# pwrseq_me18 register map
Registers are access not given, no defined reset value unless marked. A register's access mark holds for its fields unless they carry their own. Offsets are from the block's base; lines under a group give offsets from that group; [hi:lo] are bit positions; {n}, {i} and the like mark numbered series; 'fields as' and 'values as' point back to an identical list; <NAME> marks a mode.

## Memory map
0x40006800 PWRSEQ size 0x400 — Power Sequencer / Low Power Control Register.

## PWRSEQ — Power Sequencer / Low Power Control Register.
Base 0x40006800
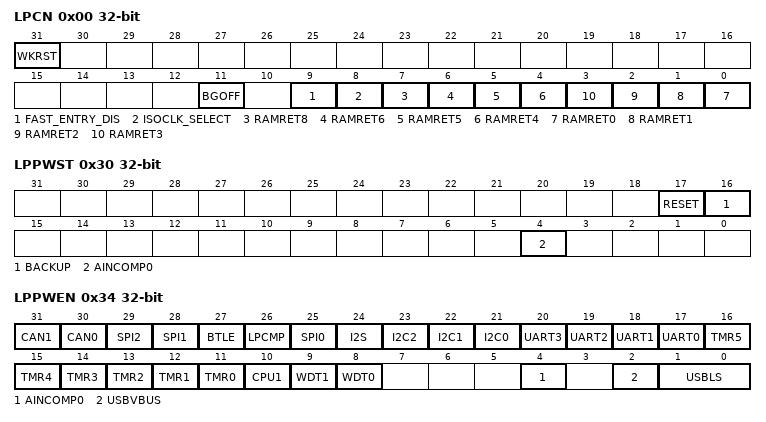
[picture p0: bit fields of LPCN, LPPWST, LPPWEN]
0x00 LPCN — Low Power Control Register.
  [31] WKRST — Reset wakeup status registers
  [11] BGOFF — Bandgap OFF. This controls the System Bandgap in DeepSleep mode.
    0=on (Bandgap is always ON.); 1=off (Bandgap is OFF in DeepSleep mode (default).)
  [9] FAST_ENTRY_DIS — Fast Low Power mode entry disable
  [8] ISOCLK_SELECT — 0 = PCLK 1= ISO CLK use for RISV in Low power mode
  [7] RAMRET8 — System RAM retention in BACKUP mode. RAM7 is retained if any of RAM0 to RAM6 is retained.
    0=dis (Disable Ram Retention.); 1=en (Enable System RAM 3 retention.)
  [6] RAMRET6 — System RAM retention in BACKUP mode. These two bits are used in conjuction with RREGEN bit.
    values as RAMRET8
  [5] RAMRET5 — System RAM retention in BACKUP mode. These two bits are used in conjuction with RREGEN bit.
    values as RAMRET8
  [4] RAMRET4 — System RAM retention in BACKUP mode. These two bits are used in conjuction with RREGEN bit.
    values as RAMRET8
  [n] RAMRET{n} (n=0..3) — System RAM retention in BACKUP mode. These two bits are used in conjuction with RREGEN bit.
    0=dis (Disable Ram Retention.); 1=en (Enable System RAM {n} retention.)
0x04 LPWKST0 — Low Power I/O Wakeup Status Register 0. This register indicates the low power wakeup status for GPIO0.
  [0] WAKEST — Wakeup IRQ flags (write ones to clear). One or more of these bits will be set when the corresponding dedicated GPIO pin (s) transition (s) from low to high or high to low. If GPIO wakeup source is selected, using PM.GPIOWKEN register, and the corresponding bit is also selected in LPWKEN register, an interrupt will be gnerated to wake up the CPU from a low power mode.
0x08 LPWKEN0 — Low Power I/O Wakeup Enable Register 0. This register enables low power wakeup functionality for GPIO0.
  [30:0] WAKEEN — Enable wakeup. These bits allow wakeup from the corresponding GPIO pin (s) on transition (s) from low to high or high to low when PM.GPIOWKEN is set. Wakeup status is indicated in PPWKST register.
0x0C LPWKST1 — Low Power I/O Wakeup Status Register 1. This register indicates the low power wakeup status for GPIO1.
  [9:0] WAKEST — Wakeup IRQ flags (write ones to clear). One or more of these bits will be set when the corresponding dedicated GPIO pin (s) transition (s) from low to high or high to low. If GPIO wakeup source is selected, using PM.GPIOWKEN register, and the corresponding bit is also selected in LPWKEN register, an interrupt will be gnerated to wake up the CPU from a low power mode.
0x10 LPWKEN1 — Low Power I/O Wakeup Enable Register 1. This register enables low power wakeup functionality for GPIO1.
  [9:0] WAKEEN — Enable wakeup. These bits allow wakeup from the corresponding GPIO pin (s) on transition (s) from low to high or high to low when PM.GPIOWKEN is set. Wakeup status is indicated in PPWKST register.
0x14 LPWKST2 — Low Power I/O Wakeup Status Register 2. This register indicates the low power wakeup status for GPIO2.
  [7:0] WAKEST — Wakeup IRQ flags (write ones to clear). One or more of these bits will be set when the corresponding dedicated GPIO pin (s) transition (s) from low to high or high to low. If GPIO wakeup source is selected, using PM.GPIOWKEN register, and the corresponding bit is also selected in LPWKEN register, an interrupt will be gnerated to wake up the CPU from a low power mode.
0x18 LPWKEN2 — Low Power I/O Wakeup Enable Register 2. This register enables low power wakeup functionality for GPIO2.
  [7:0] WAKEEN — Enable wakeup. These bits allow wakeup from the corresponding GPIO pin (s) on transition (s) from low to high or high to low when PM.GPIOWKEN is set. Wakeup status is indicated in PPWKST register.
0x1C LPWKST3 — Low Power I/O Wakeup Status Register 3. This register indicates the low power wakeup status for GPIO3.
  [1:0] WAKEST — Wakeup IRQ flags (write ones to clear). One or more of these bits will be set when the corresponding dedicated GPIO pin (s) transition (s) from low to high or high to low. If GPIO wakeup source is selected, using PM.GPIOWKEN register, and the corresponding bit is also selected in LPWKEN register, an interrupt will be gnerated to wake up the CPU from a low power mode.
0x20 LPWKEN3 — Low Power I/O Wakeup Enable Register 3. This register enables low power wakeup functionality for GPIO3.
  [1:0] WAKEEN — Enable wakeup. These bits allow wakeup from the corresponding GPIO pin (s) on transition (s) from low to high or high to low when PM.GPIOWKEN is set. Wakeup status is indicated in PPWKST register.
0x24 LPWKST4 — Low Power I/O Wakeup Status Register 4. This register indicates the low power wakeup status for GPIO4.
  fields as LPWKST3
0x28 LPWKEN4 — Low Power I/O Wakeup Enable Register 4. This register enables low power wakeup functionality for GPIO4.
  fields as LPWKEN3
0x30 LPPWST — Low Power Peripheral Wakeup Status Register.
  [17] RESET — Reset Detected Wakeup Flag.
  [16] BACKUP — Backup Mode Wakeup Flag.
  [4] AINCOMP0 — Analog Input Comparator Wakeup Flag.
0x34 LPPWEN — Low Power Peripheral Wakeup Enable Register.
  [31] CAN1 — CAN1 Wakeup Enable. This bit allows wakeup from the CAN1.
  [30] CAN0 — CAN0 Wakeup Enable. This bit allows wakeup from the CAN0.
  [29] SPI2 — SPI2 Wakeup Enable. This bit allows wakeup from the SPI2.
  [28] SPI1 — SPI1 Wakeup Enable. This bit allows wakeup from the SPI1.
  [27] BTLE — BTLE Wakeup Enable. This bit allows wakeup from the BTLE.
  [26] LPCMP — LPCMP Wakeup Enable. This bit allows wakeup from the LPCMP.
  [25] SPI0 — SPI0 Wakeup Enable. This bit allows wakeup from the SPI0.
  [24] I2S — I2S Wakeup Enable. This bit allows wakeup from the I2S.
  [23] I2C2 — I2C2 Wakeup Enable. This bit allows wakeup from the I2C2.
  [22] I2C1 — I2C1 Wakeup Enable. This bit allows wakeup from the I2C1.
  [21] I2C0 — I2C0 Wakeup Enable. This bit allows wakeup from the I2C0.
  [n+17] UART{n} (n=0..3) — UART{n} Wakeup Enable. This bit allows wakeup from the UART{n}.
  [n+11] TMR{n} (n=0..5) — TMR{n} Wakeup Enable. This bit allows wakeup from the TMR{n}.
  [10] CPU1 — CPU1 Wakeup Enable. This bit allows wakeup from the CPU1.
  [9] WDT1 — WDT1 Wakeup Enable. This bit allows wakeup from the WDT1.
  [8] WDT0 — WDT0 Wakeup Enable. This bit allows wakeup from the WDT0.
  [4] AINCOMP0 — AINCOMP0 Wakeup Enable. This bit allows wakeup from the AINCOMP0.
  [2] USBVBUS — USB VBUS Detect Wakeup Enable. This bit allows wakeup from the USB power supply on or off status.
  [1:0] USBLS — USB UTMI Linestate Detect Wakeup Enable. These bits allow wakeup from the corresponding USB linestate signal(s) on transition(s) from low to high or high to low when PM.USBWKEN is set.
0x48 GP0 — General Purpose Register 0
0x4C GP1 — General Purpose Register 1
